# AT32UC3C0128C device description
Architecture: AVR32_UC3; Family: AVR UC3
Registers are 32-bit, read-write, reset 0x0 unless marked. A register's access mark holds for its fields unless they carry their own. Offsets are from the block's base; [hi:lo] are bit positions; lines under a group give offsets from that group; {n}, {i} and the like mark numbered series; 'fields as' and 'values as' point back to an identical list.

## AW — aWire
Instances: AW 0xffff7000
0x00 CTRL — Control Register
  [1:0] MODE
    0=DISABLED; 1=RECEIVE; 2=TRANSMIT; 3=RECEIVESYNC
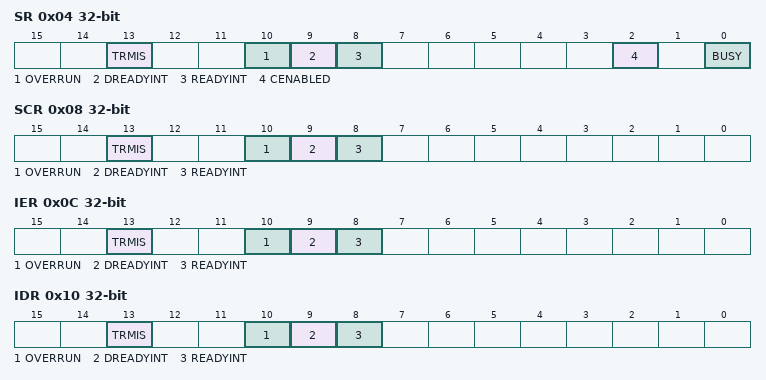
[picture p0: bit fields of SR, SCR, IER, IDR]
0x04 SR ro — Status Register
  [13] TRMIS — Transmit Mismatch
  [10] OVERRUN — Data Overrun
  [9] DREADYINT — Data Ready Interrupt
  [8] READYINT — Ready Interrupt
  [2] CENABLED — Clock Enabled
  [0] BUSY — Synchronizer Busy
0x08 SCR wo reset not defined — Status Clear Register
  [13] TRMIS — Transmit Mismatch
  [10] OVERRUN — Data Overrun
  [9] DREADYINT — Data Ready Interrupt
  [8] READYINT — Ready Interrupt
0x0C IER wo reset not defined — Interrupt Enable Register
  fields as SCR
0x10 IDR wo reset not defined — Interrupt Disable Register
  fields as SCR
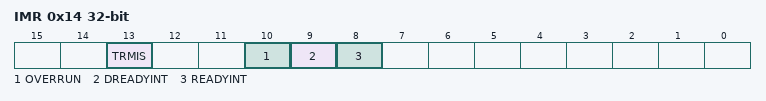
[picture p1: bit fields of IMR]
0x14 IMR ro — Interrupt Mask Register
  fields as SCR
0x18 RHR ro — Receive Holding Register
  [7:0] RXDATA — Received Data
0x1C THR — Transmit Holding Register
  [7:0] TXDATA — Transmit Data
0x20 BRR — Baud Rate Register
  [15:0] BR — Baud Rate
0x24 VERSION ro reset not defined
  [11:0] VERSION — Version Number
0x28 CLKR — Clock Request Register
  [0] CLKEN — Clock Enable
    0=DISABLE; 1=ENABLE

## CANIF — Control Area Network interface
Instances: CANIF 0xfffd1c00
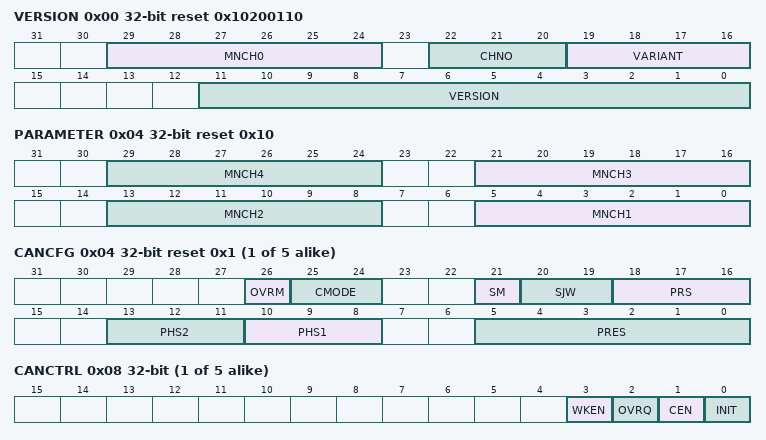
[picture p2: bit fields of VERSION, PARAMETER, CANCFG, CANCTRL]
0x00 VERSION ro reset 0x10200110
  [29:24] MNCH0 — MNCH0 bit(s)
  [22:20] CHNO — CHNO bit(s)
  [19:16] VARIANT — VARIANT bit(s)
  [11:0] VERSION — VERSION bit(s)
0x04 PARAMETER ro reset 0x10
  [8n-3:8n-8] MNCH{n} (n=1..4) — MNCH{n} bit(s)
{0x8+0x200*i} CHANNEL[{i}] (i=0..4) group
  0x00 CANRAMB
    [31:0] RAMBASE — RAMBASE bit(s)
  0x04 CANCFG reset 0x1
    [26] OVRM — OVRM bit(s)
    [25:24] CMODE — CMODE bit(s)
    [21] SM — SM bit(s)
    [20:19] SJW — SJW bit(s)
    [18:16] PRS — PRS bit(s)
    [13:11] PHS2 — PHS2 bit(s)
    [10:8] PHS1 — PHS1 bit(s)
    [5:0] PRES — PRES bit(s)
  0x08 CANCTRL
    [3] WKEN — WKEN bit(s)
    [2] OVRQ — OVRQ bit(s)
    [1] CEN — CEN bit(s)
    [0] INIT — INIT bit(s)
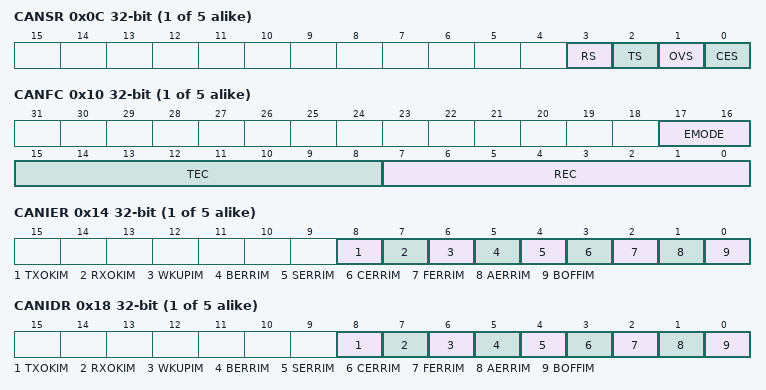
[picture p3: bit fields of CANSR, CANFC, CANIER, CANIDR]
  0x0C CANSR ro
    [3] RS — RS bit(s)
    [2] TS — TS bit(s)
    [1] OVS — OVS bit(s)
    [0] CES — CES bit(s)
  0x10 CANFC ro
    [17:16] EMODE — EMODE bit(s)
    [15:8] TEC — TEC bit(s)
    [7:0] REC — REC bit(s)
  0x14 CANIER wo
    [8] TXOKIM — TXOKIM bit(s)
    [7] RXOKIM — RXOKIM bit(s)
    [6] WKUPIM — WKUPIM bit(s)
    [5] BERRIM — BERRIM bit(s)
    [4] SERRIM — SERRIM bit(s)
    [3] CERRIM — CERRIM bit(s)
    [2] FERRIM — FERRIM bit(s)
    [1] AERRIM — AERRIM bit(s)
    [0] BOFFIM — BOFFIM bit(s)
  0x18 CANIDR wo
    fields as CHANNEL[0].CANIER
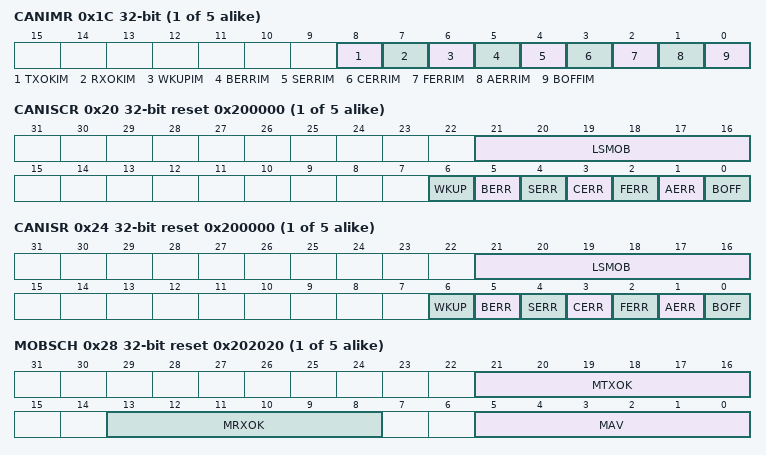
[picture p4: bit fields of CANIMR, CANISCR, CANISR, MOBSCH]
  0x1C CANIMR ro
    fields as CHANNEL[0].CANIER
  0x20 CANISCR wo reset 0x200000
    [21:16] LSMOB — LSMOB bit(s)
    [6] WKUP — WKUP bit(s)
    [5] BERR — BERR bit(s)
    [4] SERR — SERR bit(s)
    [3] CERR — CERR bit(s)
    [2] FERR — FERR bit(s)
    [1] AERR — AERR bit(s)
    [0] BOFF — BOFF bit(s)
  0x24 CANISR ro reset 0x200000
    fields as CHANNEL[0].CANISCR
  0x28 MOBSCH ro reset 0x202020
    [21:16] MTXOK — MTXOK bit(s)
    [13:8] MRXOK — MRXOK bit(s)
    [5:0] MAV — MAV bit(s)
  0x2C MOBER wo
    [31:0] MEN — MEN bit(s)
  0x30 MOBDR wo
    [31:0] MEN — MEN bit(s)
  0x34 MOBESR ro
    [31:0] MEN — MEN bit(s)
  0x38 MOBIER wo
    [31:0] MIM — MIM bit(s)
  0x3C MOBIDR wo
    [31:0] MIM — MIM bit(s)
  0x40 MOBIMR ro
    [31:0] MIM — MIM bit(s)
  0x44 MRXISCR wo
    [31:0] RXOK — RXOK bit(s)
  0x48 MRXISR ro
    [31:0] RXOK — RXOK bit(s)
  0x4C MTXISCR wo
    [31:0] TXOK — TXOK bit(s)
  0x50 MTXISR ro
    [31:0] TXOK — TXOK bit(s)
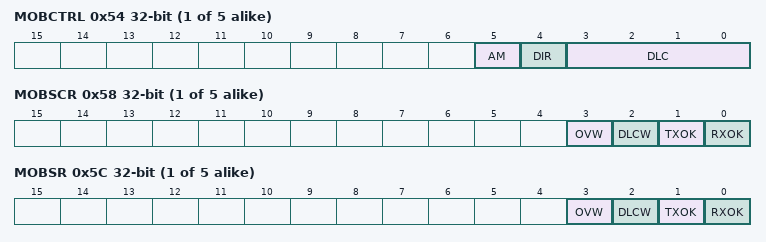
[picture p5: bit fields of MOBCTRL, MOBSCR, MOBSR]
  0x54 MOBCTRL
    [5] AM — AM bit(s)
    [4] DIR — DIR bit(s)
    [3:0] DLC — DLC bit(s)
  0x58 MOBSCR wo
    [3] OVW — OVW bit(s)
    [2] DLCW — DLCW bit(s)
    [1] TXOK — TXOK bit(s)
    [0] RXOK — RXOK bit(s)
  0x5C MOBSR ro
    fields as CHANNEL[0].MOBSCR

## DACIFB — DAC interface
Instances: DACIFB0 0xffff6800, DACIFB1 0xffff6c00
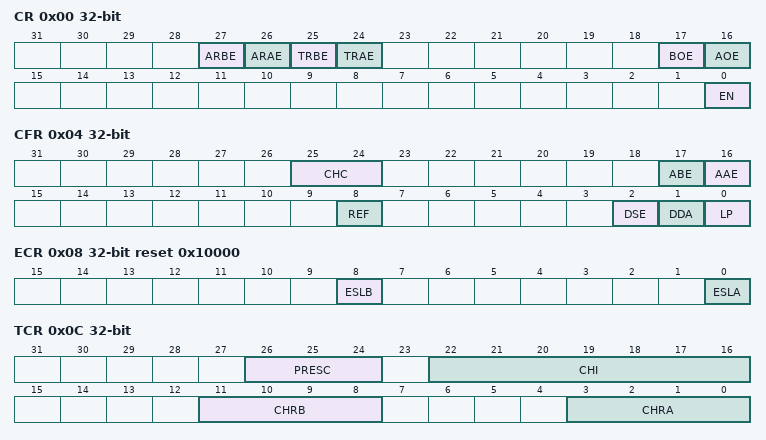
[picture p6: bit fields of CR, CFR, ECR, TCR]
0x00 CR
  [27] ARBE — ARBE bit(s)
  [26] ARAE — ARAE bit(s)
  [25] TRBE — TRBE bit(s)
  [24] TRAE — TRAE bit(s)
  [17] BOE — BOE bit(s)
  [16] AOE — AOE bit(s)
  [0] EN — EN bit(s)
0x04 CFR
  [25:24] CHC — CHC bit(s)
  [17] ABE — ABE bit(s)
  [16] AAE — AAE bit(s)
  [8] REF — REF bit(s)
  [2] DSE — DSE bit(s)
  [1] DDA — DDA bit(s)
  [0] LP — LP bit(s)
0x08 ECR reset 0x10000
  [8] ESLB — ESLB bit(s)
  [0] ESLA — ESLA bit(s)
0x0C TCR
  [26:24] PRESC — PRESC bit(s)
  [22:16] CHI — CHI bit(s)
  [11:8] CHRB — CHRB bit(s)
  [3:0] CHRA — CHRA bit(s)
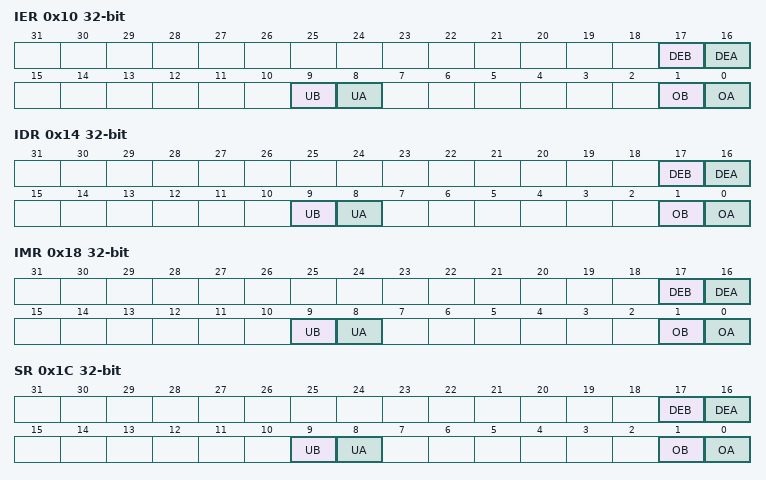
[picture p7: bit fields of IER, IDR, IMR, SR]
0x10 IER
  [17] DEB — DEB bit(s)
  [16] DEA — DEA bit(s)
  [9] UB — UB bit(s)
  [8] UA — UA bit(s)
  [1] OB — OB bit(s)
  [0] OA — OA bit(s)
0x14 IDR
  fields as IER
0x18 IMR ro
  fields as IER
0x1C SR ro
  fields as IER
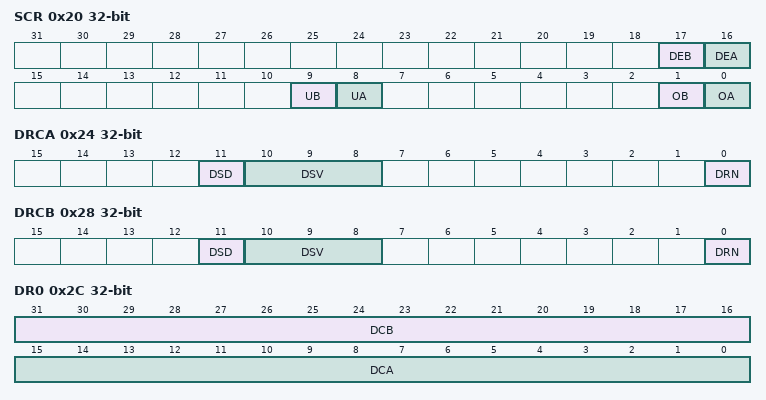
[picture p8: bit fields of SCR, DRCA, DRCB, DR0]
0x20 SCR
  fields as IER
0x24 DRCA
  [11] DSD — DSD bit(s)
  [10:8] DSV — DSV bit(s)
  [0] DRN — DRN bit(s)
0x28 DRCB
  fields as DRCA
0x2C DR0
  [31:16] DCB — DCB bit(s)
  [15:0] DCA — DCA bit(s)
0x30 DR1
  [15:0] DCB — DCB bit(s)
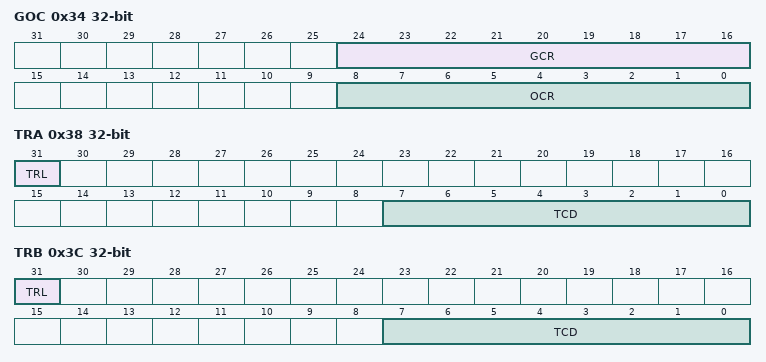
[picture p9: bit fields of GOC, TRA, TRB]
0x34 GOC
  [24:16] GCR — GCR bit(s)
  [8:0] OCR — OCR bit(s)
0x38 TRA
  [31] TRL — TRL bit(s)
  [7:0] TCD — TCD bit(s)
0x3C TRB
  [31] TRL — TRL bit(s)
  [7:0] TCD — TCD bit(s)
0x40 VERSION ro reset 0x110
  [11:0] VER — VER bit(s)
